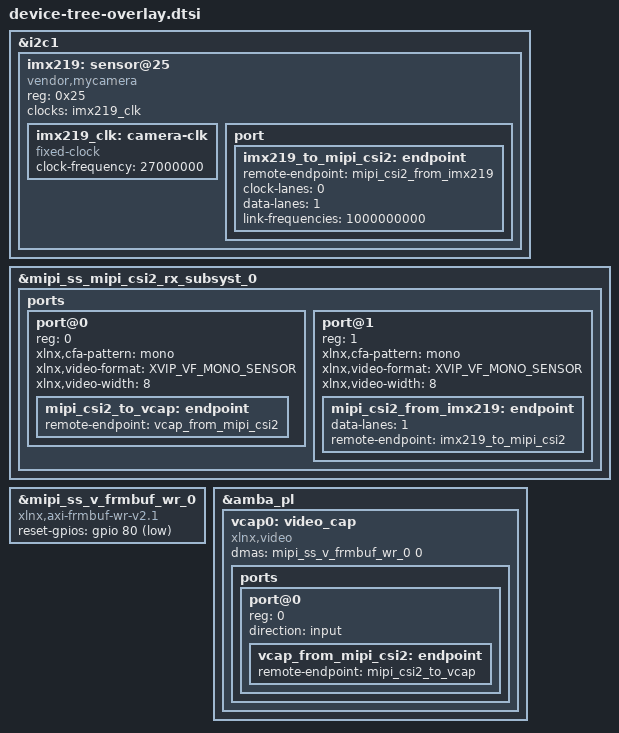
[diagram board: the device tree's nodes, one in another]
/*
Since I want to dump raw greyscale frames from my camera (MONO 8 Greyscale pixel format), 
I have bypassed these 3 blocks in device-tree: demosaic, gamma_lut and proc_ss. 
I thought that these 3 blocks are mainly for color-processing and my camera is mono/ greyscale, 
so I have bypassed them in device tree. 

location: project-spec/meta-user/recipes-bsp/device-tree/files/pl-custom.dtsi

My pl-custom looks like this -
*/

#include <dt-bindings/media/xilinx-vip.h>
#include <dt-bindings/gpio/gpio.h>

&i2c1 {
	#address-cells = <1>;
	#size-cells = <0>;
	imx219: sensor@25 {               // I2C address from spec
		compatible = "vendor,mycamera";
		reg = <0x25>;
		clocks = <&imx219_clk>;
		clock-names = "xclk";

		imx219_clk: camera-clk {
			compatible = "fixed-clock";
			#clock-cells = <0>;
			clock-frequency = <27000000>;
		};

		port {
			imx219_to_mipi_csi2: endpoint {
				remote-endpoint = <&mipi_csi2_from_imx219>;
				clock-lanes = <0>;
				data-lanes = <1>;                       // data-lane as 1 - from spec
				// clock-noncontinuous;                 // clock continuous
				link-frequencies = /bits/ 64 <1000000000>;      // spec
			};
		};
	};
};


&mipi_ss_mipi_csi2_rx_subsyst_0 {
	ports {
		#address-cells = <1>;
		#size-cells = <0>;
		port@0 {
			reg = <0>;
			xlnx,cfa-pattern = "mono";                 // changed rggb to mono
			xlnx,video-format = <XVIP_VF_MONO_SENSOR>;
			xlnx,video-width = <8>;
			
			mipi_csi2_to_vcap: endpoint {               // directly send to video_cap (xlnx,video)
				remote-endpoint = <&vcap_from_mipi_csi2>;
			};
			
		};
		port@1 {
			reg = <1>;
			xlnx,cfa-pattern = "mono";                  // changed rggb to mono
			xlnx,video-format = <XVIP_VF_MONO_SENSOR>;
			xlnx,video-width = <8>;
			mipi_csi2_from_imx219: endpoint {
				data-lanes = <1>;                         // changed to 1
				remote-endpoint = <&imx219_to_mipi_csi2>;
			};
		};
	};
};

/*
    Bypassed demosaic, gamma_lut, proc_ss

    &mipi_ss_v_demosaic_0 { ... }
    &mipi_ss_v_gamma_lut_0 { ... }
    &mipi_ss_v_proc_ss_0 { ... }
*/

&mipi_ss_v_frmbuf_wr_0 {
	compatible = "xlnx,axi-frmbuf-wr-v2.1";
	reset-gpios = <&gpio 80 GPIO_ACTIVE_LOW>;
};

&amba_pl {
	vcap0: video_cap {
		compatible = "xlnx,video";
		dmas = <&mipi_ss_v_frmbuf_wr_0 0>;
		dma-names = "port0";
		ports {
			#address-cells = <1>;
			#size-cells = <0>;
			port@0 {
				reg = <0>;
				direction = "input";
				
				vcap_from_mipi_csi2: endpoint {
					remote-endpoint = <&mipi_csi2_to_vcap>;
				};
				
			};
		};
	};
};
